# STM32F429ZITx register map
Registers are 32-bit, read-only, reset 0x0 unless marked. A register's access mark holds for its fields unless they carry their own. Offsets are from the block's base; lines under a group give offsets from that group; [hi:lo] are bit positions; {n}, {i} and the like mark numbered series; 'fields as' and 'values as' point back to an identical list; <NAME> marks a mode.

## Memory map
0x40020000 GPIOA

## GPIOA
Base 0x40020000
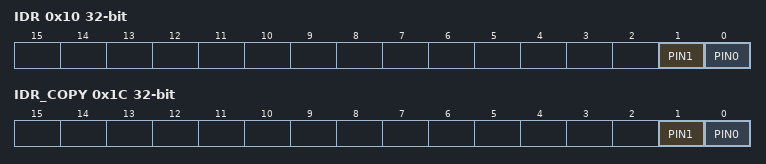
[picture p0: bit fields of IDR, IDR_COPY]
0x10 IDR
  [1] PIN1, [0] PIN0
0x14 EVENT read-clears
0x18 COMMAND wo
0x1C IDR_COPY
  [1] PIN1, [0] PIN0
{0x100+0x20*i} CHANNEL{i} (i=0..1) group
  0x00 VALUE 16-bit
